# M031AE_v1 register map
File version: 1.0
Registers are 32-bit, read-write, reset 0x0 unless marked. A register's access mark holds for its fields unless they carry their own. Offsets are from the block's base; [hi:lo] are bit positions; {n}, {i} and the like mark numbered series.

## RTC — RTC Register Map
Base 0x40041000
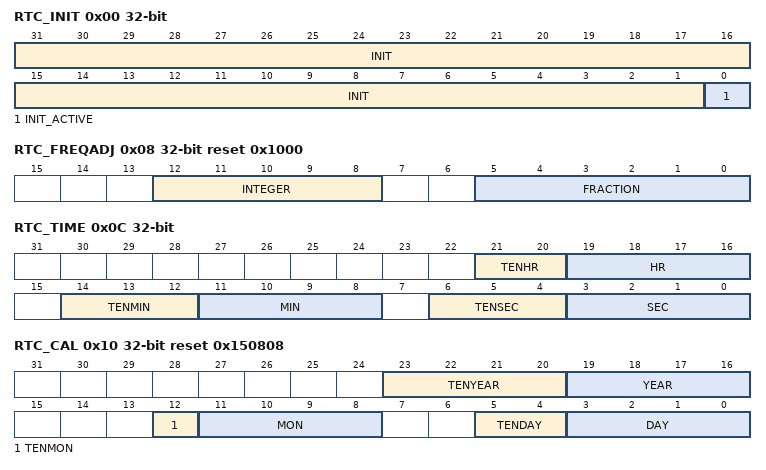
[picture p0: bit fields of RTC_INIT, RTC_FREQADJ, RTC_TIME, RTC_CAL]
0x00 RTC_INIT — RTC Initiation Register
  [31:1] INIT wo — RTC Initiation (Write Only). When RTC block is powered on, RTC is at reset state. User has to write a number (0x a5eb1357) to INIT to make RTC leave reset state. Once the INIT is written as 0xa5eb1357, the RTC will be in un-reset state permanently. The INIT is a write-only field and read value will be always 0.
  [0] INIT_ACTIVE ro — RTC Active Status (Read Only)
    0=RTC is at reset state; 1=RTC is at normal active state
0x08 RTC_FREQADJ reset 0x1000 — RTC Frequency Compensation Register
  [12:8] INTEGER — Integer Part
    {v}=Integer part of detected value is {v+32752} (v=0..31)
  [5:0] FRACTION — Fraction Part. Note: Digit in FCR must be expressed as hexadecimal number.
0x0C RTC_TIME — RTC Time Loading Register
  [21:20] TENHR — 10-Hour Time Digit (0~2)When RTC runs as 12-hour time scale mode, RTC_TIME[21] (the high bit of TENHR[1:0]) means AM/PM indication (If RTC_TIME[21] is 1, it indicates PM time message.)
  [19:16] HR — 1-Hour Time Digit (0~9)
  [14:12] TENMIN — 10-Min Time Digit (0~5)
  [11:8] MIN — 1-Min Time Digit (0~9)
  [6:4] TENSEC — 10-Sec Time Digit (0~5)
  [3:0] SEC — 1-Sec Time Digit (0~9)
0x10 RTC_CAL reset 0x150808 — RTC Calendar Loading Register
  [23:20] TENYEAR — 10-Year Calendar Digit (0~9)
  [19:16] YEAR — 1-Year Calendar Digit (0~9)
  [12] TENMON — 10-Month Calendar Digit (0~1)
  [11:8] MON — 1-Month Calendar Digit (0~9)
  [5:4] TENDAY — 10-Day Calendar Digit (0~3)
  [3:0] DAY — 1-Day Calendar Digit (0~9)
0x14 RTC_CLKFMT reset 0x1 — RTC Time Scale Selection Register
  [0] _24HEN — 24-hour / 12-hour Time Scale Selection. Indicates that RTC_TIME and RTC_TALM are in 24-hour time scale or 12-hour time scale
    0=12-hour time scale with AM and PM indication selected; 1=24-hour time scale selected
0x18 RTC_WEEKDAY reset 0x6 — RTC Day of the Week Register
  [2:0] WEEKDAY — Day of the Week Register
    0=Sunday; 1=Monday; 2=Tuesday; 3=Wednesday; 4=Thursday; 5=Friday; 6=Saturday
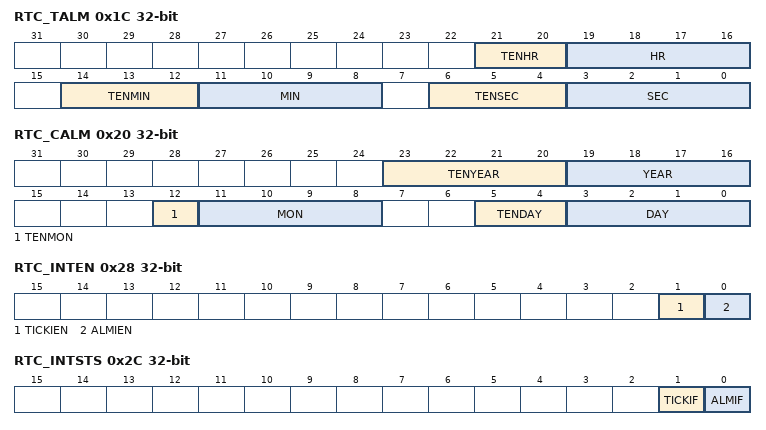
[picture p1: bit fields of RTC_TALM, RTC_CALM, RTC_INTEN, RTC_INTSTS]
0x1C RTC_TALM — RTC Time Alarm Register
  [21:20] TENHR — 10-Hour Time Digit of Alarm Setting (0~2)When RTC runs as 12-hour time scale mode, RTC_TIME[21] (the high bit of TENHR[1:0]) means AM/PM indication (If RTC_TIME[21] is 1, it indicates PM time message.)
  [19:16] HR — 1-Hour Time Digit of Alarm Setting (0~9)
  [14:12] TENMIN — 10-Min Time Digit of Alarm Setting (0~5)
  [11:8] MIN — 1-Min Time Digit of Alarm Setting (0~9)
  [6:4] TENSEC — 10-Sec Time Digit of Alarm Setting (0~5)
  [3:0] SEC — 1-Sec Time Digit of Alarm Setting (0~9)
0x20 RTC_CALM — RTC Calendar Alarm Register
  [23:20] TENYEAR — 10-Year Calendar Digit of Alarm Setting (0~9)
  [19:16] YEAR — 1-Year Calendar Digit of Alarm Setting (0~9)
  [12] TENMON — 10-Month Calendar Digit of Alarm Setting (0~1)
  [11:8] MON — 1-Month Calendar Digit of Alarm Setting (0~9)
  [5:4] TENDAY — 10-Day Calendar Digit of Alarm Setting (0~3)
  [3:0] DAY — 1-Day Calendar Digit of Alarm Setting (0~9)
0x24 RTC_LEAPYEAR ro — RTC Leap Year Indicator Register
  [0] LEAPYEAR — Leap Year Indication (Read Only)
    0=This year is not a leap year; 1=This year is leap year
0x28 RTC_INTEN — RTC Interrupt Enable Register
  [1] TICKIEN — Time Tick Interrupt Enable Bit. Set TICKIEN to 1 can also enable chip wake-up function when RTC tick interrupt event is generated.
    0=RTC Time Tick interrupt Disabled; 1=RTC Time Tick interrupt Enabled
  [0] ALMIEN — Alarm Interrupt Enable Bit. Set ALMIEN to 1 can also enable chip wake-up function when RTC alarm interrupt event is generated.
    0=RTC Alarm interrupt Disabled; 1=RTC Alarm interrupt Enabled
0x2C RTC_INTSTS — RTC Interrupt Status Register
  [1] TICKIF — RTC Time Tick Interrupt Flag. Note: Write 1 to clear this bit.
    0=Tick condition did not occur; 1=Tick condition occurred
  [0] ALMIF — RTC Alarm Interrupt Flag. Note: Write 1 to clear this bit.
    0=Alarm condition is not matched; 1=Alarm condition is matched
0x30 RTC_TICK — RTC Time Tick Register
  [2:0] TICK — Time Tick Register. These bits are used to select RTC time tick period for Periodic Time Tick Interrupt request.
    0=Time tick is 1 second; 1=Time tick is 1/2 second; 2=Time tick is 1/4 second; 3=Time tick is 1/8 second; 4=Time tick is 1/16 second; 5=Time tick is 1/32 second; 6=Time tick is 1/64 second; 7=Time tick is 1/128 second
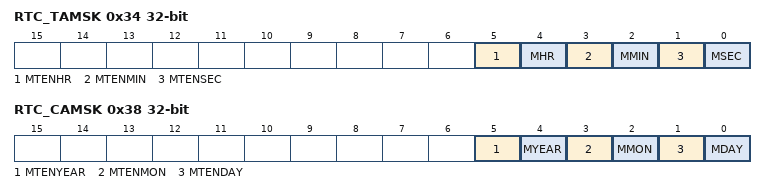
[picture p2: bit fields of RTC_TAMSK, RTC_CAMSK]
0x34 RTC_TAMSK — RTC Time Alarm Mask Register
  [5] MTENHR — Mask 10-Hour Time Digit of Alarm Setting (0~2)
  [4] MHR — Mask 1-Hour Time Digit of Alarm Setting (0~9)
  [3] MTENMIN — Mask 10-Min Time Digit of Alarm Setting (0~5)
  [2] MMIN — Mask 1-Min Time Digit of Alarm Setting (0~9)
  [1] MTENSEC — Mask 10-Sec Time Digit of Alarm Setting (0~5)
  [0] MSEC — Mask 1-Sec Time Digit of Alarm Setting (0~9)
0x38 RTC_CAMSK — RTC Calendar Alarm Mask Register
  [5] MTENYEAR — Mask 10-Year Calendar Digit of Alarm Setting (0~9)
  [4] MYEAR — Mask 1-Year Calendar Digit of Alarm Setting (0~9)
  [3] MTENMON — Mask 10-Month Calendar Digit of Alarm Setting (0~1)
  [2] MMON — Mask 1-Month Calendar Digit of Alarm Setting (0~9)
  [1] MTENDAY — Mask 10-Day Calendar Digit of Alarm Setting (0~3)
  [0] MDAY — Mask 1-Day Calendar Digit of Alarm Setting (0~9)
0x100 RTC_LXTCTL — RTC 32K.768 KHz LXT Control Register
  [7] OSC32_S — Clock 32K Source Selection
    0=Clock source from LXT32K; 1=Clock source from LIRC38K
